AUTOSAR XML (schema 00044)
package /ComponentTypes
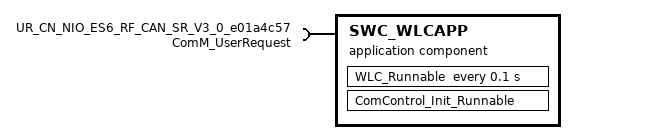
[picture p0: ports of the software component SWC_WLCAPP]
  application sw component type SWC_WLCAPP
    require port UR_CN_NIO_ES6_RF_CAN_SR_V3_0_e01a4c57: required-com-specs=[RequestComMode, GetCurrentComMode, GetMaxComMode, GetRequestedComMode], required-interface=ComM_UserRequest
    behavior SWC_WLCAPP_InternalBehavior
      init event ComControl_Init_Runnable_InitEvent: start-on-event=ComControl_Init_Runnable
      timing event TMT_WLC_Runnable: start-on-event=WLC_Runnable, period=0.1
      runnable ComControl_Init_Runnable
        4 x sync call:
          SC_UR_CN_NIO_ES6_RF_CAN_SR_V3_0_e01a4c57_GetCurrentComMode: operation=UR_CN_NIO_ES6_RF_CAN_SR_V3_0_e01a4c57.GetCurrentComMode
          SC_UR_CN_NIO_ES6_RF_CAN_SR_V3_0_e01a4c57_GetMaxComMode: operation=UR_CN_NIO_ES6_RF_CAN_SR_V3_0_e01a4c57.GetMaxComMode
          SC_UR_CN_NIO_ES6_RF_CAN_SR_V3_0_e01a4c57_GetRequestedComMode: operation=UR_CN_NIO_ES6_RF_CAN_SR_V3_0_e01a4c57.GetRequestedComMode
          SC_UR_CN_NIO_ES6_RF_CAN_SR_V3_0_e01a4c57_RequestComMode: operation=UR_CN_NIO_ES6_RF_CAN_SR_V3_0_e01a4c57.RequestComMode
      runnable WLC_Runnable
  swc implementation SWC_WLCAPP_Implementation: behavior=SWC_WLCAPP_InternalBehavior
